AUTOSAR XML (schema 4-0-3)
standard types defined: Boolean, UInt16, UInt8
package /AUTOSAR_Platform/DataConstrs
  range DC_Boolean: raw 0..1
  range DC_UInt16: raw 0..65535
package /PATAC/MSM/ComponentTypes
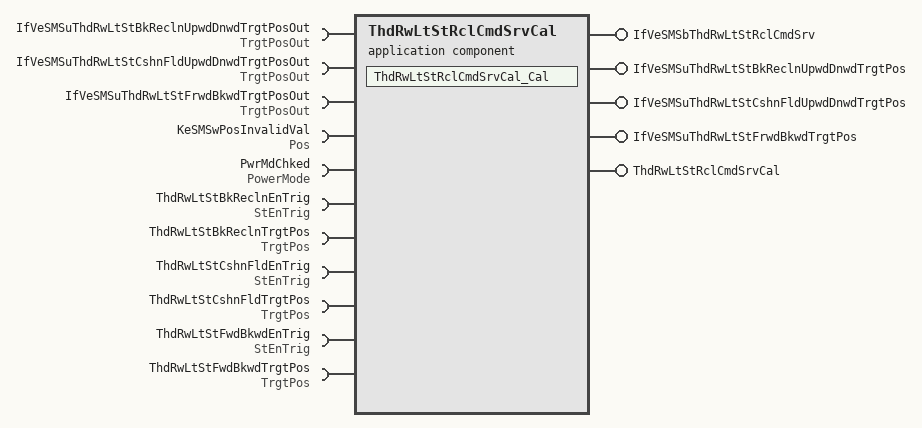
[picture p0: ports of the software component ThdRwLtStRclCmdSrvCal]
  application sw component type ThdRwLtStRclCmdSrvCal
    5 x provide port:
      IfVeSMSbThdRwLtStRclCmdSrv: nonqueued-sender-com-spec{data-element=IfVeSMSbThdRwLtStRclCmdSrv/Val, init-value=0}, provided-interface=IfVeSMSbThdRwLtStRclCmdSrv
      IfVeSMSuThdRwLtStBkReclnUpwdDnwdTrgtPos: nonqueued-sender-com-spec{data-element=IfVeSMSuThdRwLtStBkReclnUpwdDnwdTrgtPos/Val, init-value=4095}, provided-interface=IfVeSMSuThdRwLtStBkReclnUpwdDnwdTrgtPos
      IfVeSMSuThdRwLtStCshnFldUpwdDnwdTrgtPos: nonqueued-sender-com-spec{data-element=IfVeSMSuThdRwLtStCshnFldUpwdDnwdTrgtPos/Val, init-value=4095}, provided-interface=IfVeSMSuThdRwLtStCshnFldUpwdDnwdTrgtPos
      IfVeSMSuThdRwLtStFrwdBkwdTrgtPos: nonqueued-sender-com-spec{data-element=IfVeSMSuThdRwLtStFrwdBkwdTrgtPos/Val, init-value=4095}, provided-interface=IfVeSMSuThdRwLtStFrwdBkwdTrgtPos
      ThdRwLtStRclCmdSrvCal: server-com-spec{operation=Cal, queue-length=1}, provided-interface=ThdRwLtStRclCmdSrvCal
    11 x require port:
      IfVeSMSuThdRwLtStBkReclnUpwdDnwdTrgtPosOut: nonqueued-receiver-com-spec{data-element=TrgtPosOut/Val, filter=data-filter-type=ALWAYS, init-value=0}, required-interface=TrgtPosOut
      IfVeSMSuThdRwLtStCshnFldUpwdDnwdTrgtPosOut: nonqueued-receiver-com-spec{data-element=TrgtPosOut/Val, filter=data-filter-type=ALWAYS, init-value=0}, required-interface=TrgtPosOut
      IfVeSMSuThdRwLtStFrwdBkwdTrgtPosOut: nonqueued-receiver-com-spec{data-element=TrgtPosOut/Val, filter=data-filter-type=ALWAYS, init-value=0}, required-interface=TrgtPosOut
      KeSMSwPosInvalidVal: parameter-require-com-spec{init-value=4095, parameter=Val}, required-interface=Pos
      PwrMdChked: nonqueued-receiver-com-spec{data-element=PowerMode/Val, filter=data-filter-type=ALWAYS, init-value=0}, required-interface=PowerMode
      ThdRwLtStBkReclnEnTrig: nonqueued-receiver-com-spec{data-element=StEnTrig/Val, filter=data-filter-type=ALWAYS, init-value=0}, required-interface=StEnTrig
      ThdRwLtStBkReclnTrgtPos: nonqueued-receiver-com-spec{data-element=TrgtPos/Val, filter=data-filter-type=ALWAYS, init-value=4095}, required-interface=TrgtPos
      ThdRwLtStCshnFldEnTrig: nonqueued-receiver-com-spec{data-element=StEnTrig/Val, filter=data-filter-type=ALWAYS, init-value=0}, required-interface=StEnTrig
      ThdRwLtStCshnFldTrgtPos: nonqueued-receiver-com-spec{data-element=TrgtPos/Val, filter=data-filter-type=ALWAYS, init-value=4095}, required-interface=TrgtPos
      ThdRwLtStFwdBkwdEnTrig: nonqueued-receiver-com-spec{data-element=StEnTrig/Val, filter=data-filter-type=ALWAYS, init-value=0}, required-interface=StEnTrig
      ThdRwLtStFwdBkwdTrgtPos: nonqueued-receiver-com-spec{data-element=TrgtPos/Val, filter=data-filter-type=ALWAYS, init-value=4095}, required-interface=TrgtPos
    behavior ThdRwLtStRclCmdSrvCal_InternalBehavior
      operation invoked event OIT_ThdRwLtStRclCmdSrvCal_Cal_ThdRwLtStRclCmdSrvCal_Cal: start-on-event=ThdRwLtStRclCmdSrvCal_Cal, operation=ThdRwLtStRclCmdSrvCal.Cal
      runnable ThdRwLtStRclCmdSrvCal_Cal
        data-receive-point-by-arguments:
          10 x access:
            REC_IfVeSMSuThdRwLtStBkReclnUpwdDnwdTrgtPosOut_Val: accessed-variable=IfVeSMSuThdRwLtStBkReclnUpwdDnwdTrgtPosOut.Val
            REC_IfVeSMSuThdRwLtStCshnFldUpwdDnwdTrgtPosOut_Val: accessed-variable=IfVeSMSuThdRwLtStCshnFldUpwdDnwdTrgtPosOut.Val
            REC_IfVeSMSuThdRwLtStFrwdBkwdTrgtPosOut_Val: accessed-variable=IfVeSMSuThdRwLtStFrwdBkwdTrgtPosOut.Val
            REC_PwrMdChked_Val: accessed-variable=PwrMdChked.Val
            REC_ThdRwLtStBkReclnEnTrig_Val: accessed-variable=ThdRwLtStBkReclnEnTrig.Val
            REC_ThdRwLtStBkReclnTrgtPos_Val: accessed-variable=ThdRwLtStBkReclnTrgtPos.Val
            REC_ThdRwLtStCshnFldEnTrig_Val: accessed-variable=ThdRwLtStCshnFldEnTrig.Val
            REC_ThdRwLtStCshnFldTrgtPos_Val: accessed-variable=ThdRwLtStCshnFldTrgtPos.Val
            REC_ThdRwLtStFwdBkwdEnTrig_Val: accessed-variable=ThdRwLtStFwdBkwdEnTrig.Val
            REC_ThdRwLtStFwdBkwdTrgtPos_Val: accessed-variable=ThdRwLtStFwdBkwdTrgtPos.Val
        data-send-points:
          4 x access:
            SEND_IfVeSMSbThdRwLtStRclCmdSrv_Val: accessed-variable=IfVeSMSbThdRwLtStRclCmdSrv.Val
            SEND_IfVeSMSuThdRwLtStBkReclnUpwdDnwdTrgtPos_Val: accessed-variable=IfVeSMSuThdRwLtStBkReclnUpwdDnwdTrgtPos.Val
            SEND_IfVeSMSuThdRwLtStCshnFldUpwdDnwdTrgtPos_Val: accessed-variable=IfVeSMSuThdRwLtStCshnFldUpwdDnwdTrgtPos.Val
            SEND_IfVeSMSuThdRwLtStFrwdBkwdTrgtPos_Val: accessed-variable=IfVeSMSuThdRwLtStFrwdBkwdTrgtPos.Val
        parameter access PA_KeSMSwPosInvalidVal_Val: accessed-parameter=KeSMSwPosInvalidVal.Val
  swc implementation ThdRwLtStRclCmdSrvCal_Implementation: behavior=ThdRwLtStRclCmdSrvCal_InternalBehavior
    code-descriptors:
      code Default: artifact-descriptors=autosar-engineering-object={short-label=Default, category=SWSRC}
package /PATAC/MSM/ModeAdjust/CalPortInterface
  parameter interface Pos
    parameter data prototype Val: sw-calibration-access=READ-WRITE, type=UInt16
package /PATAC/MSM/ModeAdjust/DataType
  impl type PowerMode1: category=VALUE, base-type=UInt8, sw-calibration-access=READ-ONLY, compu {0=PowerMode_Off, 1=PowerMode_Acc, 2=PowerMode_Run, 3=PowerMode_Crank, 4=PowerMode_Invalid}, type-emitter=RTE
package /PATAC/MSM/ModeAdjust/Interfaces
  sender receiver interface IfVeSMSbThdRwLtStRclCmdSrv: invalidation-policy{data-element=IfVeSMSbThdRwLtStRclCmdSrv/Val, handle-invalid=DONT-INVALIDATE}
    data Val: type=Boolean
  sender receiver interface IfVeSMSuThdRwLtStCshnFldUpwdDnwdTrgtPos: invalidation-policy{data-element=IfVeSMSuThdRwLtStCshnFldUpwdDnwdTrgtPos/Val, handle-invalid=DONT-INVALIDATE}
    data Val: type=UInt16
package /PATAC/MSM/ModeAdjust/PortInterface
  client server interface ThdRwLtStRclCmdSrvCal
    operation Cal
  sender receiver interface PowerMode: invalidation-policy{data-element=PowerMode/Val, handle-invalid=DONT-INVALIDATE}
    data Val: type=PowerMode1
  sender receiver interface StEnTrig: invalidation-policy{data-element=StEnTrig/Val, handle-invalid=DONT-INVALIDATE}
    data Val: type=Boolean
  sender receiver interface TrgtPosOut: invalidation-policy{data-element=TrgtPosOut/Val, handle-invalid=DONT-INVALIDATE}
    data Val: type=Boolean
package /PATAC/MSM/PortInterfaces
  sender receiver interface IfVeSMSuThdRwLtStBkReclnUpwdDnwdTrgtPos: invalidation-policy{data-element=IfVeSMSuThdRwLtStBkReclnUpwdDnwdTrgtPos/Val, handle-invalid=DONT-INVALIDATE}
    data Val: type=UInt16
  sender receiver interface IfVeSMSuThdRwLtStFrwdBkwdTrgtPos: invalidation-policy{data-element=IfVeSMSuThdRwLtStFrwdBkwdTrgtPos/Val, handle-invalid=DONT-INVALIDATE}
    data Val: type=UInt16
  sender receiver interface TrgtPos: invalidation-policy{data-element=TrgtPos/Val, handle-invalid=DONT-INVALIDATE}
    data Val: type=UInt16
